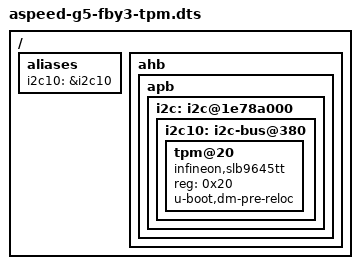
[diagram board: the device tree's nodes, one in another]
/dts-v1/;

#include "aspeed-g5.dtsi"

/ {
        aliases {
                i2c10 = &i2c10;
        };

        ahb {
                apb {
                        i2c: i2c@1e78a000 {
                                i2c10: i2c-bus@380 {
                                        tpm@20 {
                                                /* Emulators should use atmel,at97sc3204t. */
                                                compatible = "infineon,slb9645tt";
                                                reg = <0x20>;
                                                u-boot,dm-pre-reloc;
                                        };
                                };
                        };
          };
        };
};
